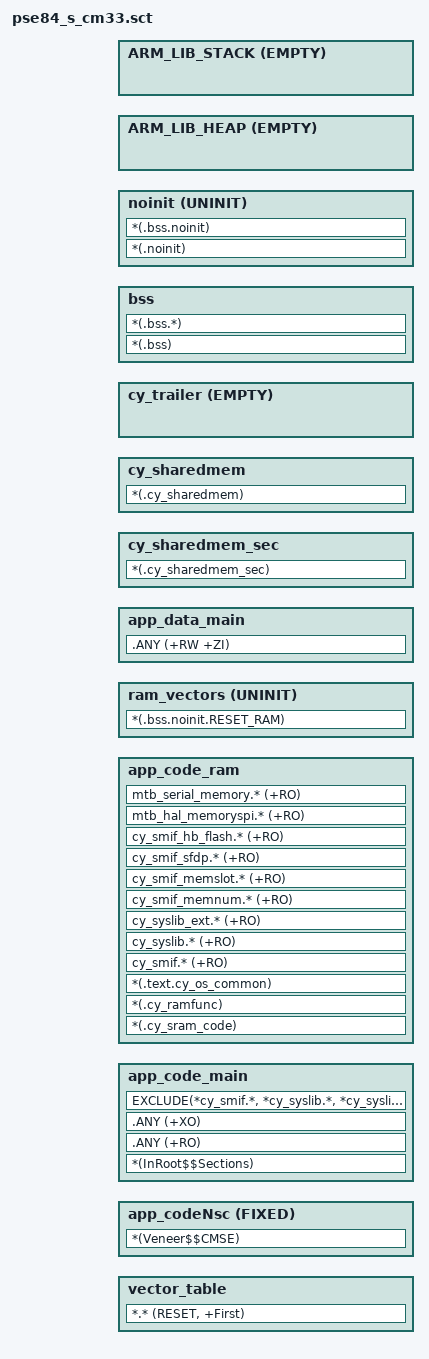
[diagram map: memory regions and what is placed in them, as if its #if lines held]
#! armclang -E --target=arm-arm-none-eabi -mcpu=cortex-m33 -xc
; command above MUST be in first line (no comment above!)
/***************************************************************************//**
* \file pse84_s_cm33.sct
* \version 1.0.0
*
* scatter file for the armclang C compiler.
*
* The main purpose of this file is to describe how the sections in the
* input files should be mapped into the output file, and to control the memory
* layout of the output file.
*
*
* \note The linker files included with the PDL template projects must be
* generic and handle all common use cases. Your project may not use every
* section defined in the linker files. In that case you may see the warnings
* during the build process: L6314W (no section matches pattern) and/or L6329W
* (pattern only matches removed unused sections). In your project, you can
* suppress the warning by passing the "--diag_suppress=L6314W,L6329W" option to
* the linker, simply comment out or remove the relevant code in the linker
* file.
*
********************************************************************************
* \copyright
* Copyright (c) (2020-2025), Cypress Semiconductor Corporation (an Infineon company) or
* an affiliate of Cypress Semiconductor Corporation.
* SPDX-License-Identifier: Apache-2.0
*
* Licensed under the Apache License, Version 2.0 (the "License");
* you may not use this file except in compliance with the License.
* You may obtain a copy of the License at
*
*     http://www.apache.org/licenses/LICENSE-2.0
*
* Unless required by applicable law or agreed to in writing, software
* distributed under the License is distributed on an "AS IS" BASIS,
* WITHOUT WARRANTIES OR CONDITIONS OF ANY KIND, either express or implied.
* See the License for the specific language governing permissions and
* limitations under the License.
*******************************************************************************/

/* Include the device memory definitions generated by the Device Configurator */
#include "../../config/GeneratedSource/cymem_armlink_CM33_0_S.sct"

/* Define the stack size for the application */
/* To set stack size in application add makefile ldflags: --predefine="-DAPP_MSP_STACK_SIZE=<CUSTOM_VALUE>" */
#ifdef APP_MSP_STACK_SIZE
#define __STACK_SIZE    APP_MSP_STACK_SIZE
#else
#define __STACK_SIZE    0x00000800
#endif

/* User Stack & Heap boundary definition */
/* Place the top of the stack at the end of the m33s_data_S */
#define __STACK_TOP    (CYMEM_CM33_0_S_m33s_data_S_START + CYMEM_CM33_0_S_m33s_data_SIZE)
/* Position the beginning of the heap right after the noinit ER, ensuring an 8-byte alignment */
#define __HEAP_BASE    AlignExpr(ImageLimit(noinit), 8)
/* The heap extends to the stack */
#define __HEAP_SIZE    (__STACK_TOP - __STACK_SIZE - __HEAP_BASE)

/* Device definitions */
#define VECTORS_ALIGNMENT 0x400

/* The size of the MCU boot header area at the start of main code region */
#define MCUBOOT_HEADER_SIZE  0x400


/* Serial Memory Interface block #0 memory #1, 16 MB */
/* Start address is offset by MCUBOOT_HEADER_SIZE to let the area free for the MCU boot header */
LR_XIP_PORT0 (CYMEM_CM33_0_S_m33s_nvm_sel_S_START + MCUBOOT_HEADER_SIZE) (CYMEM_CM33_0_S_m33s_nvm_SIZE - MCUBOOT_HEADER_SIZE)
{

  vector_table (CYMEM_CM33_0_S_m33s_nvm_sel_S_START + MCUBOOT_HEADER_SIZE) ALIGN VECTORS_ALIGNMENT
  {
    *.* (RESET, +First)
  }

  app_codeNsc AlignExpr(ImageLimit(vector_table), 32) FIXED
  {
    *(Veneer$$CMSE)
  }

  /* The execution region is designated for the main secure (S) application code for the Cortex-M33 */
  /* Performance-sensitive or critical functions that need to be executed in sram are manually excluded */
  app_code_main AlignExpr(ImageLimit(app_codeNsc), 32) ALIGN 32 (CYMEM_CM33_0_S_m33s_nvm_SIZE - MCUBOOT_HEADER_SIZE - VECTORS_ALIGNMENT)
  {
    *(InRoot$$Sections)
    .ANY (+RO)
    .ANY (+XO)
    EXCLUDE(*cy_smif.*, *cy_syslib.*, *cy_syslib_ext.*, *cy_smif_memnum.*, *cy_smif_memslot.*, *cy_smif_sfdp.*, *cy_smif_hb_flash.*, *mtb_hal_memoryspi.*, *mtb_serial_memory.*)
  }


  /* The execution region for performance-sensitive or critical functions that need to be executed in SRAM */
  app_code_ram CYMEM_CM33_0_S_m33s_code_S_START ALIGN 4 CYMEM_CM33_0_S_m33s_code_SIZE
  {
    *(.cy_sram_code)
    *(.cy_ramfunc)
    *(.text.cy_os_common)
    cy_smif.* (+RO)
    cy_syslib.* (+RO)
    cy_syslib_ext.* (+RO)
    cy_smif_memnum.* (+RO)
    cy_smif_memslot.* (+RO)
    cy_smif_sfdp.* (+RO)
    cy_smif_hb_flash.* (+RO)
    mtb_hal_memoryspi.* (+RO)
    mtb_serial_memory.* (+RO)
  }

  /* A region for the vector table */
  ram_vectors AlignExpr(CYMEM_CM33_0_S_m33s_data_S_START, VECTORS_ALIGNMENT) ALIGN VECTORS_ALIGNMENT UNINIT CYMEM_CM33_0_S_m33s_data_SIZE
  {
    *(.bss.noinit.RESET_RAM)
  }

  /* The execution region for initialized data memory */
  app_data_main AlignExpr(ImageLimit(ram_vectors), 4) ALIGN 4 CYMEM_CM33_0_S_m33s_data_SIZE
  {
    .ANY (+RW +ZI)
  }

  /* A region for secure shared RAM memory */
  cy_sharedmem_sec CYMEM_CM33_0_S_m33s_shared_S_START CYMEM_CM33_0_S_m33s_shared_SIZE
  {
    *(.cy_sharedmem_sec)
  }

  /* A region for public shared RAM memory only the Cortex-M33 Secure can allocate data but all cores can access*/
  cy_sharedmem CYMEM_CM33_0_S_m33s_allocatable_shared_S_START CYMEM_CM33_0_S_m33s_allocatable_shared_SIZE
  {
    *(.cy_sharedmem)
  }

  /* A reserved region for the trail space for the signature used by the bootloader - do not place any code here */
  cy_trailer (CYMEM_CM33_0_S_m33s_trailer_sel_S_START) EMPTY CYMEM_CM33_0_S_m33s_trailer_SIZE
  {
  }

}


/* SRAM, 1 MB */
/* Note. This load region must not contain any loadable data; only UNINIT or BSS execution regions are allowed */
LR_SRAM CYMEM_CM33_0_S_m33s_data_S_START CYMEM_CM33_0_S_m33s_data_SIZE
{

  /* A section for non-initialized data memory */
  bss AlignExpr(ImageLimit(app_data_main), 8) ALIGN 8 (CYMEM_CM33_0_S_m33s_data_SIZE - AlignExpr(ImageLength(ram_vectors), VECTORS_ALIGNMENT) - AlignExpr(ImageLength(app_data_main), 4))
  {
    *(.bss)
    *(.bss.*)
  }

  /* A region for variables that should not be initialized during the device startup */
  noinit AlignExpr(ImageLimit(bss), 4) ALIGN 4 UNINIT (CYMEM_CM33_0_S_m33s_data_SIZE - AlignExpr(ImageLength(ram_vectors), VECTORS_ALIGNMENT) - AlignExpr(ImageLength(app_data_main), 4) - AlignExpr(ImageLength(bss), 4))
  {
    *(.noinit)
    *(.bss.noinit)
  }

  /* A region for the heap memory */
  ARM_LIB_HEAP __HEAP_BASE EMPTY __HEAP_SIZE
  {
  }

  /* A region for stack */
  ARM_LIB_STACK __STACK_TOP EMPTY -__STACK_SIZE
  {
  }
}
